VERSION ""

NS_ :

BS_:

BU_: DBW AKit Pacifica MPDM_Master MPDM_Requester

BO_ 3221225472 VECTOR__INDEPENDENT_SIG_MSG: 0 Vector__XXX
 SG_ DBW_PrndStateCmdMir : 4|3@1+ (1,0) [0|4] "Enum" Vector__XXX
 SG_ DBW_PrndParkBrakeStatus : 16|2@1+ (1,0) [0|3] "Enum" Vector__XXX
 SG_ AKit_PrndCtrlMode : 49|1@1+ (1,0) [0|1] "Bool" Vector__XXX
 SG_ AKit_PrndCtrlEnblCmd : 48|1@1+ (1,0) [0|1] "Bool" Vector__XXX
 SG_ AKit_MiscVehicleEnable : 0|1@1+ (1,0) [0|0] "" Vector__XXX

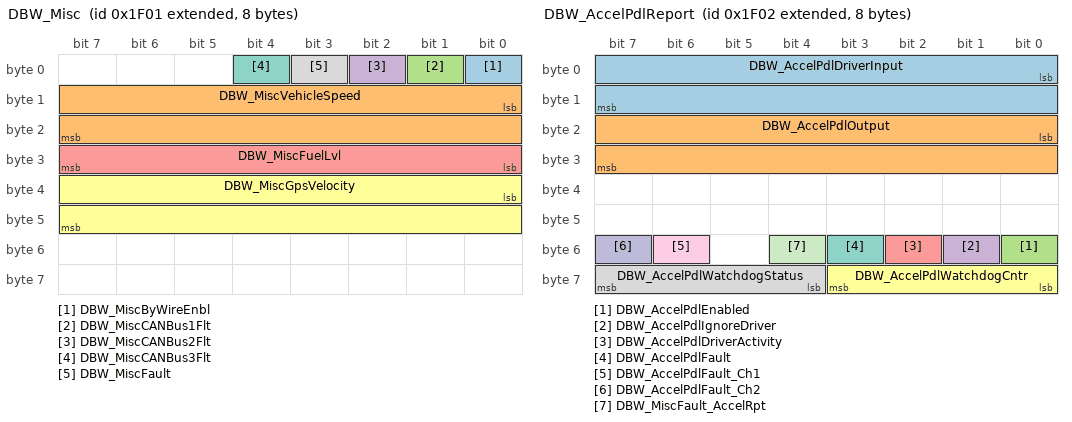
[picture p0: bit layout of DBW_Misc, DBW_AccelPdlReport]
BO_ 2147491585 DBW_Misc: 8 DBW
 SG_ DBW_MiscByWireEnbl : 0|1@1+ (1,0) [0|1] "Bool" Vector__XXX
 SG_ DBW_MiscVehicleSpeed : 8|16@1+ (0.0078125,0) [0|511.984] "km/h" Vector__XXX
 SG_ DBW_MiscCANBus1Flt : 1|1@1+ (1,0) [0|1] "Bool" Vector__XXX
 SG_ DBW_MiscCANBus2Flt : 2|1@1+ (1,0) [0|1] "Bool" Vector__XXX
 SG_ DBW_MiscFuelLvl : 24|8@1+ (0.5,0) [0|100] "%" Vector__XXX
 SG_ DBW_MiscGpsVelocity : 32|16@1+ (1,0) [0|0] "" Vector__XXX
 SG_ DBW_MiscCANBus3Flt : 4|1@1+ (1,0) [0|1] "Bool" Vector__XXX
 SG_ DBW_MiscFault : 3|1@1+ (1,0) [0|1] "Bool" Vector__XXX

BO_ 2147491586 DBW_AccelPdlReport: 8 DBW
 SG_ DBW_AccelPdlDriverInput : 0|16@1+ (1,0) [0|100] "%" Vector__XXX
 SG_ DBW_AccelPdlOutput : 16|16@1+ (1,0) [0|100] "%" Vector__XXX
 SG_ DBW_AccelPdlEnabled : 48|1@1+ (1,0) [0|1] "Bool" Vector__XXX
 SG_ DBW_AccelPdlIgnoreDriver : 49|1@1+ (1,0) [0|1] "Bool" Vector__XXX
 SG_ DBW_AccelPdlDriverActivity : 50|1@1+ (1,0) [0|1] "Bool" Vector__XXX
 SG_ DBW_AccelPdlWatchdogCntr : 56|4@1+ (1,0) [0|15] "" Vector__XXX
 SG_ DBW_AccelPdlFault : 51|1@1+ (1,0) [0|1] "Bool" Vector__XXX
 SG_ DBW_AccelPdlWatchdogStatus : 60|4@1+ (1,0) [0|15] "enum" Vector__XXX
 SG_ DBW_AccelPdlFault_Ch1 : 54|1@1+ (1,0) [0|1] "Bool" Vector__XXX
 SG_ DBW_AccelPdlFault_Ch2 : 55|1@1+ (1,0) [0|1] "Bool" Vector__XXX
 SG_ DBW_MiscFault_AccelRpt : 52|1@1+ (1,0) [0|1] "Bool" Vector__XXX

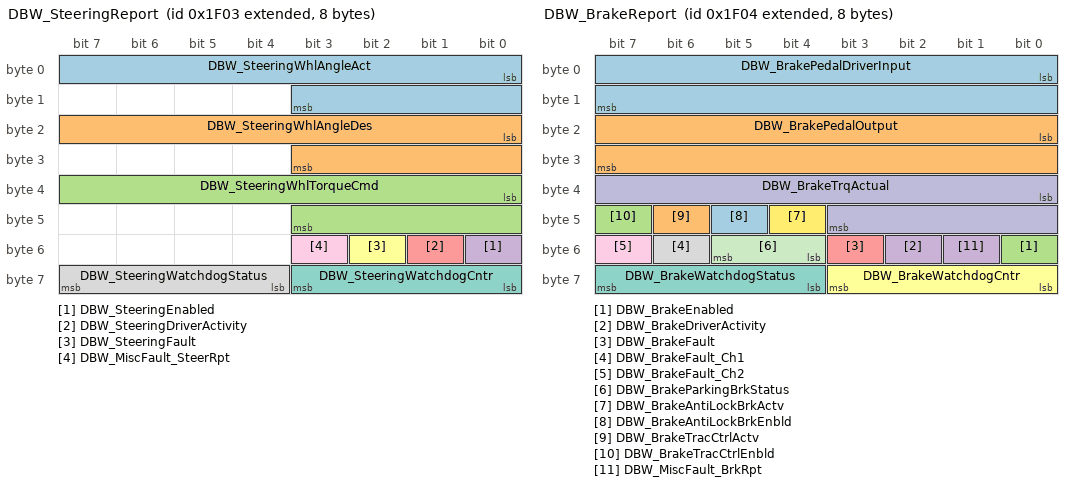
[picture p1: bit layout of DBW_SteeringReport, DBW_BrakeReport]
BO_ 2147491587 DBW_SteeringReport: 8 DBW
 SG_ DBW_SteeringWhlAngleAct : 0|12@1- (0.5,0) [-600|600] "deg" Vector__XXX
 SG_ DBW_SteeringWhlAngleDes : 16|12@1- (0.5,0) [-600|600] "deg" Vector__XXX
 SG_ DBW_SteeringWhlTorqueCmd : 32|12@1- (0.0078125,0) [-8|7.99219] "Nm" Vector__XXX
 SG_ DBW_SteeringEnabled : 48|1@1+ (1,0) [0|1] "Bool" Vector__XXX
 SG_ DBW_SteeringDriverActivity : 49|1@1+ (1,0) [0|1] "Bool" Vector__XXX
 SG_ DBW_SteeringFault : 50|1@1+ (1,0) [0|1] "Bool" Vector__XXX
 SG_ DBW_SteeringWatchdogCntr : 56|4@1+ (1,0) [0|15] "" Vector__XXX
 SG_ DBW_SteeringWatchdogStatus : 60|4@1+ (1,0) [0|15] "enum" Vector__XXX
 SG_ DBW_MiscFault_SteerRpt : 51|1@1+ (1,0) [0|1] "Bool" Vector__XXX

BO_ 2147491588 DBW_BrakeReport: 8 DBW
 SG_ DBW_BrakePedalDriverInput : 0|16@1+ (1,0) [0|100] "%" Vector__XXX
 SG_ DBW_BrakePedalOutput : 16|16@1+ (1,0) [0|100] "%" Vector__XXX
 SG_ DBW_BrakeEnabled : 48|1@1+ (1,0) [0|1] "Bool" Vector__XXX
 SG_ DBW_BrakeDriverActivity : 50|1@1+ (1,0) [0|1] "Bool" Vector__XXX
 SG_ DBW_BrakeFault : 51|1@1+ (1,0) [0|1] "Bool" Vector__XXX
 SG_ DBW_BrakeWatchdogCntr : 56|4@1+ (1,0) [0|15] "" Vector__XXX
 SG_ DBW_BrakeWatchdogStatus : 60|4@1+ (1,0) [0|15] "enum" Vector__XXX
 SG_ DBW_BrakeFault_Ch1 : 54|1@1+ (1,0) [0|1] "Bool" Vector__XXX
 SG_ DBW_BrakeFault_Ch2 : 55|1@1+ (1,0) [0|1] "Bool" Vector__XXX
 SG_ DBW_BrakeTrqActual : 32|12@1+ (3,0) [0|12282] "Nm" Vector__XXX
 SG_ DBW_BrakeParkingBrkStatus : 52|2@1+ (1,0) [0|3] "Enum" Vector__XXX
 SG_ DBW_BrakeAntiLockBrkActv : 44|1@1+ (1,0) [0|1] "Bool" Vector__XXX
 SG_ DBW_BrakeAntiLockBrkEnbld : 45|1@1+ (1,0) [0|1] "Bool" Vector__XXX
 SG_ DBW_BrakeTracCtrlActv : 46|1@1+ (1,0) [0|1] "Bool" Vector__XXX
 SG_ DBW_BrakeTracCtrlEnbld : 47|1@1+ (1,0) [0|1] "Bool" Vector__XXX
 SG_ DBW_MiscFault_BrkRpt : 49|1@1+ (1,0) [0|1] "Bool" Vector__XXX

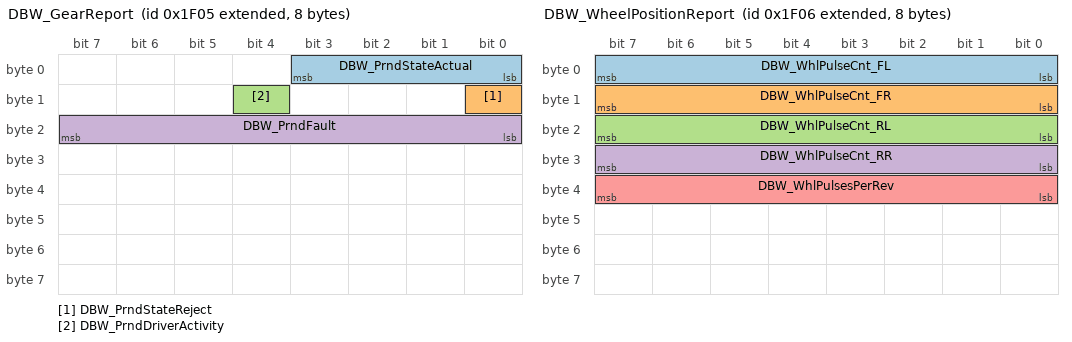
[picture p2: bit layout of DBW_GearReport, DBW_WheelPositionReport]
BO_ 2147491589 DBW_GearReport: 8 DBW
 SG_ DBW_PrndStateActual : 0|4@1+ (1,0) [0|4] "Enum" Vector__XXX
 SG_ DBW_PrndStateReject : 8|1@1+ (1,0) [0|1] "Bool" Vector__XXX
 SG_ DBW_PrndDriverActivity : 12|1@1+ (1,0) [0|1] "Bool" Vector__XXX
 SG_ DBW_PrndFault : 16|8@1+ (1,0) [0|1] "Bool" Vector__XXX

BO_ 2147491590 DBW_WheelPositionReport: 8 DBW
 SG_ DBW_WhlPulseCnt_FL : 0|8@1+ (1,0) [0|254] "Count" Vector__XXX
 SG_ DBW_WhlPulseCnt_FR : 8|8@1+ (1,0) [0|254] "Count" Vector__XXX
 SG_ DBW_WhlPulseCnt_RL : 16|8@1+ (1,0) [0|254] "Count" Vector__XXX
 SG_ DBW_WhlPulseCnt_RR : 24|8@1+ (1,0) [0|254] "Count" Vector__XXX
 SG_ DBW_WhlPulsesPerRev : 32|8@1+ (1,0) [0|255] "Count" Vector__XXX

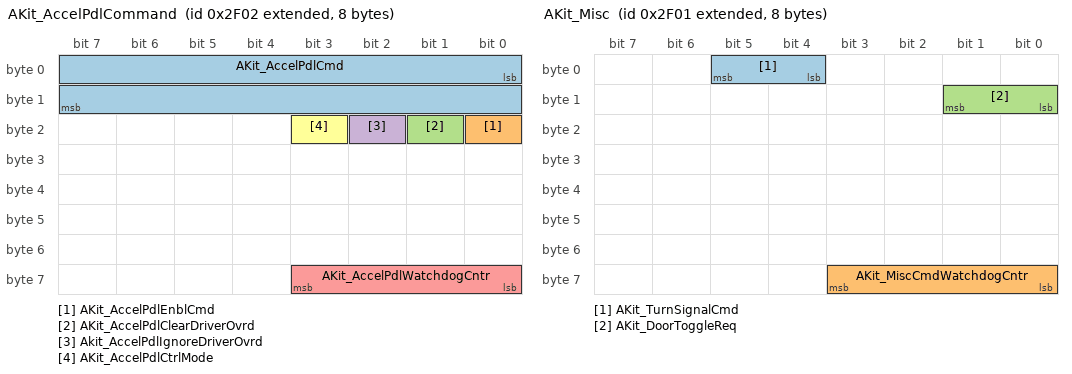
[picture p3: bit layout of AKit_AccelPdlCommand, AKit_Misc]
BO_ 2147495682 AKit_AccelPdlCommand: 8 AKit
 SG_ AKit_AccelPdlCmd : 0|16@1+ (1,0) [0|100] "%" Vector__XXX
 SG_ AKit_AccelPdlEnblCmd : 16|1@1+ (1,0) [0|1] "Bool" Vector__XXX
 SG_ AKit_AccelPdlClearDriverOvrd : 17|1@1+ (1,0) [0|1] "Bool" Vector__XXX
 SG_ Akit_AccelPdlIgnoreDriverOvrd : 18|1@1+ (1,0) [0|1] "Bool" Vector__XXX
 SG_ AKit_AccelPdlWatchdogCntr : 56|4@1+ (1,0) [0|15] "" Vector__XXX
 SG_ AKit_AccelPdlCtrlMode : 19|1@1+ (1,0) [0|1] "Enum" Vector__XXX

BO_ 2147495681 AKit_Misc: 8 AKit
 SG_ AKit_TurnSignalCmd : 4|2@1+ (1,0) [0|3] "Enum" Vector__XXX
 SG_ AKit_MiscCmdWatchdogCntr : 56|4@1+ (1,0) [0|15] "" Vector__XXX
 SG_ AKit_DoorToggleReq : 8|2@1+ (1,0) [0|3] "Enum" Vector__XXX

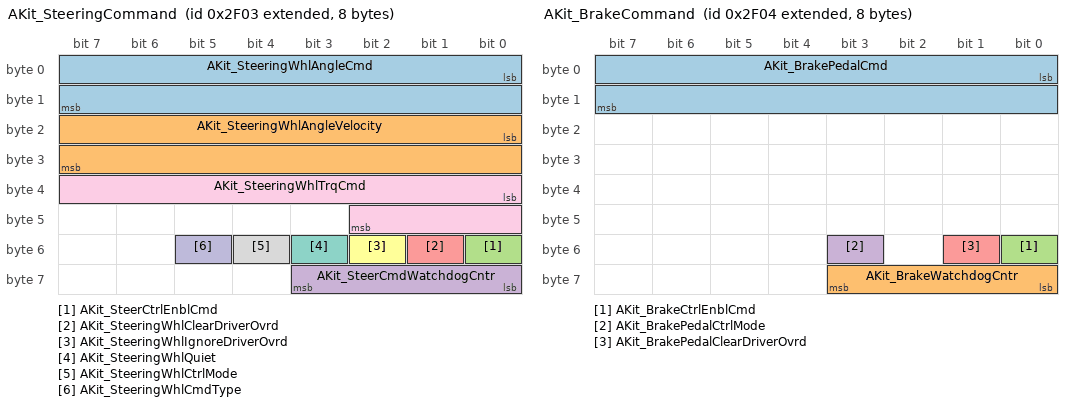
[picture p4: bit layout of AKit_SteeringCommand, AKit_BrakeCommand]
BO_ 2147495683 AKit_SteeringCommand: 8 AKit
 SG_ AKit_SteeringWhlAngleCmd : 0|16@1- (1,0) [-500|500] "deg" Vector__XXX
 SG_ AKit_SteeringWhlAngleVelocity : 16|16@1- (1,0) [0|498] "deg/s" Vector__XXX
 SG_ AKit_SteerCtrlEnblCmd : 48|1@1+ (1,0) [0|0] "" Vector__XXX
 SG_ AKit_SteerCmdWatchdogCntr : 56|4@1+ (1,0) [0|15] "" Vector__XXX
 SG_ AKit_SteeringWhlClearDriverOvrd : 49|1@1+ (1,0) [0|1] "" Vector__XXX
 SG_ AKit_SteeringWhlIgnoreDriverOvrd : 50|1@1+ (1,0) [0|1] "" Vector__XXX
 SG_ AKit_SteeringWhlQuiet : 51|1@1+ (1,0) [0|1] "" Vector__XXX
 SG_ AKit_SteeringWhlCtrlMode : 52|1@1+ (1,0) [0|0] "" Vector__XXX
 SG_ AKit_SteeringWhlTrqCmd : 32|11@1+ (0.0078125,-8) [-8|7.99219] "Nm" Vector__XXX
 SG_ AKit_SteeringWhlCmdType : 53|1@1+ (1,0) [0|1] "" Vector__XXX

BO_ 2147495684 AKit_BrakeCommand: 8 AKit
 SG_ AKit_BrakePedalCmd : 0|16@1+ (1,0) [0|100] "%" Vector__XXX
 SG_ AKit_BrakeWatchdogCntr : 56|4@1+ (1,0) [0|15] "" Vector__XXX
 SG_ AKit_BrakeCtrlEnblCmd : 48|1@1+ (1,0) [0|1] "Bool" Vector__XXX
 SG_ AKit_BrakePedalCtrlMode : 51|1@1+ (1,0) [0|1] "Enum" Vector__XXX
 SG_ AKit_BrakePedalClearDriverOvrd : 49|1@1+ (1,0) [0|1] "Bool" Vector__XXX

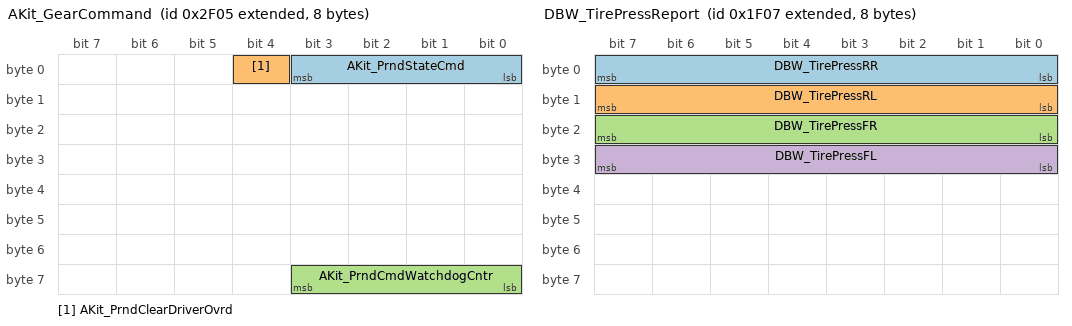
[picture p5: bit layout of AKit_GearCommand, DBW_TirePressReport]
BO_ 2147495685 AKit_GearCommand: 8 AKit
 SG_ AKit_PrndStateCmd : 0|4@1+ (1,0) [0|0] "Enum" Vector__XXX
 SG_ AKit_PrndClearDriverOvrd : 4|1@1+ (1,0) [0|0] "Bool" Vector__XXX
 SG_ AKit_PrndCmdWatchdogCntr : 56|4@1+ (1,0) [0|15] "" Vector__XXX

BO_ 2147491599 DBW_DriverInputs: 8 AKit
 SG_ DBW_OccupAnyDoorOrHoodAjar : 0|1@1+ (1,0) [0|1] "Bool" Vector__XXX
 SG_ DBW_OccupAnyAirbagDeployed : 8|1@1+ (1,0) [0|1] "Bool" Vector__XXX
 SG_ DBW_OccupAnySeatbeltUnbuckled : 16|1@1+ (1,0) [0|1] "Bool" Vector__XXX
 SG_ DBW_DrvInptCruiseResumeBtn : 24|1@1+ (1,0) [0|1] "Bool" Vector__XXX
 SG_ DBW_DrvInptCruiseCancelBtn : 25|1@1+ (1,0) [0|1] "Bool" Vector__XXX
 SG_ DBW_DrvInptCruiseAccelBtn : 26|1@1+ (1,0) [0|1] "Bool" Vector__XXX
 SG_ DBW_DrvInptCruiseDecelBtn : 27|1@1+ (1,0) [0|1] "Bool" Vector__XXX
 SG_ DBW_DrvInptCruiseOnOffBtn : 28|1@1+ (1,0) [0|1] "Bool" Vector__XXX
 SG_ DBW_DrvInptAccOnOffBtn : 29|1@1+ (1,0) [0|1] "Bool" Vector__XXX
 SG_ DBW_DrvInptAccIncDistBtn : 30|1@1+ (1,0) [0|1] "Bool" Vector__XXX
 SG_ DBW_DrvInptAccDecDistBtn : 31|1@1+ (1,0) [0|1] "Bool" Vector__XXX
 SG_ DBW_DrvInptHiBeam : 32|2@1+ (1,0) [0|3] "enum" Vector__XXX
 SG_ DBW_DrvInptTurnSignal : 34|2@1+ (1,0) [0|3] "enum" Vector__XXX
 SG_ DBW_DrvInptWiper : 36|4@1+ (1,0) [0|15] "enum" Vector__XXX
 SG_ DBW_OccupDrvDoorAjar : 1|1@1+ (1,0) [0|1] "Bool" Vector__XXX
 SG_ DBW_OccupPsgDoorAjar : 2|1@1+ (1,0) [0|1] "Bool" Vector__XXX
 SG_ DBW_OccupRlDoorAjar : 3|1@1+ (1,0) [0|1] "Bool" Vector__XXX
 SG_ DBW_OccupRrDoorAjar : 4|1@1+ (1,0) [0|1] "Bool" Vector__XXX
 SG_ DBW_OccupLiftgateAjar : 5|1@1+ (1,0) [0|1] "Bool" Vector__XXX

BO_ 2147491591 DBW_TirePressReport: 8 DBW
 SG_ DBW_TirePressRR : 0|8@1+ (6.89476,0) [0|868.739] "kPa" Vector__XXX
 SG_ DBW_TirePressRL : 8|8@1+ (6.89476,0) [0|868.739] "kPa" Vector__XXX
 SG_ DBW_TirePressFR : 16|8@1+ (6.89476,0) [0|868.739] "kPa" Vector__XXX
 SG_ DBW_TirePressFL : 24|8@1+ (6.89476,0) [0|868.739] "kPa" Vector__XXX

BO_ 2147491592 DBW_VinReport: 8 DBW
 SG_ DBW_VinMultiplexor M : 0|2@1+ (1,0) [0|2] "" Vector__XXX
 SG_ DBW_VinDigit_01 m0 : 8|8@1+ (1,0) [30|90] "ascii" Vector__XXX
 SG_ DBW_VinDigit_02 m0 : 16|8@1+ (1,0) [30|90] "ascii" Vector__XXX
 SG_ DBW_VinDigit_03 m0 : 24|8@1+ (1,0) [30|90] "ascii" Vector__XXX
 SG_ DBW_VinDigit_04 m0 : 32|8@1+ (1,0) [30|90] "ascii" Vector__XXX
 SG_ DBW_VinDigit_05 m0 : 40|8@1+ (1,0) [30|90] "ascii" Vector__XXX
 SG_ DBW_VinDigit_06 m0 : 48|8@1+ (1,0) [30|90] "ascii" Vector__XXX
 SG_ DBW_VinDigit_07 m0 : 56|8@1+ (1,0) [30|90] "ascii" Vector__XXX
 SG_ DBW_VinDigit_08 m1 : 8|8@1+ (1,0) [30|90] "ascii" Vector__XXX
 SG_ DBW_VinDigit_09 m1 : 16|8@1+ (1,0) [30|90] "ascii" Vector__XXX
 SG_ DBW_VinDigit_10 m1 : 24|8@1+ (1,0) [30|90] "ascii" Vector__XXX
 SG_ DBW_VinDigit_11 m1 : 32|8@1+ (1,0) [30|90] "ascii" Vector__XXX
 SG_ DBW_VinDigit_12 m1 : 40|8@1+ (1,0) [30|90] "ascii" Vector__XXX
 SG_ DBW_VinDigit_13 m1 : 48|8@1+ (1,0) [30|90] "ascii" Vector__XXX
 SG_ DBW_VinDigit_14 m1 : 56|8@1+ (1,0) [30|90] "ascii" Vector__XXX
 SG_ DBW_VinDigit_15 m2 : 8|8@1+ (1,0) [30|90] "ascii" Vector__XXX
 SG_ DBW_VinDigit_16 m2 : 16|8@1+ (1,0) [30|90] "ascii" Vector__XXX
 SG_ DBW_VinDigit_17 m2 : 24|8@1+ (1,0) [30|90] "ascii" Vector__XXX

BO_ 2147491593 DBW_GpsReport: 8 DBW
 SG_ DBW_GpsLong : 0|32@1+ (0.301749,0) [-648000000|648000000] "mas" Vector__XXX
 SG_ DBW_GpsLat : 32|32@1+ (0.301749,0) [-324000000|324000000] "mas" Vector__XXX

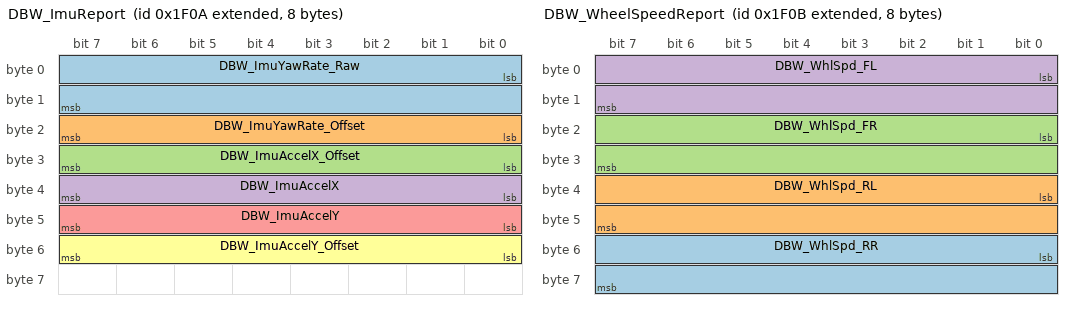
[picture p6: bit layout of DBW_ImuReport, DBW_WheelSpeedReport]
BO_ 2147491594 DBW_ImuReport: 8 DBW
 SG_ DBW_ImuYawRate_Raw : 0|16@1+ (0.01,-327.68) [-327.68|327.66] "deg/sec" Vector__XXX
 SG_ DBW_ImuYawRate_Offset : 16|8@1+ (0.08,-10.24) [-6.96|6.96] "" Vector__XXX
 SG_ DBW_ImuAccelX_Offset : 24|8@1+ (0.02,-2.56) [-2.56|2.52] "m/s/s" Vector__XXX
 SG_ DBW_ImuAccelX : 32|8@1+ (0.08,-10.24) [-10.24|10.08] "m/s/s" Vector__XXX
 SG_ DBW_ImuAccelY : 40|8@1+ (0.08,-10.24) [-10.24|10.08] "m/s/s" Vector__XXX
 SG_ DBW_ImuAccelY_Offset : 48|8@1+ (0.02,-2.56) [-2.56|2.52] "m/s/s" Vector__XXX

BO_ 2147491595 DBW_WheelSpeedReport: 8 DBW
 SG_ DBW_WhlSpd_RR : 48|16@1+ (0.5,-8192) [-8192|8191] "rpm" Vector__XXX
 SG_ DBW_WhlSpd_RL : 32|16@1+ (0.5,-8192) [-8192|8191] "rpm" Vector__XXX
 SG_ DBW_WhlSpd_FR : 16|16@1+ (0.5,-8192) [-8192|8191] "rpm" Vector__XXX
 SG_ DBW_WhlSpd_FL : 0|16@1+ (0.5,-8192) [-8192|8191] "rpm" Vector__XXX

BO_ 2147491597 Mpdm1Report: 8 MPDM_Master
 SG_ DBW_Mdpm1Fuse01 : 0|2@1+ (1,0) [0|3] "enum" Vector__XXX
 SG_ DBW_Mdpm1Fuse02 : 2|2@1+ (1,0) [0|3] "enum" Vector__XXX
 SG_ DBW_Mdpm1Fuse03 : 4|2@1+ (1,0) [0|3] "enum" Vector__XXX
 SG_ DBW_Mdpm1Fuse04 : 6|2@1+ (1,0) [0|3] "enum" Vector__XXX
 SG_ DBW_Mdpm1Fuse05 : 8|2@1+ (1,0) [0|3] "enum" Vector__XXX
 SG_ DBW_Mdpm1Fuse06 : 10|2@1+ (1,0) [0|3] "enum" Vector__XXX
 SG_ DBW_Mdpm1Fuse07 : 12|2@1+ (1,0) [0|3] "enum" Vector__XXX
 SG_ DBW_Mdpm1Fuse08 : 14|2@1+ (1,0) [0|3] "enum" Vector__XXX
 SG_ DBW_Mdpm1Fuse09 : 16|2@1+ (1,0) [0|3] "enum" Vector__XXX
 SG_ DBW_Mdpm1Fuse10 : 18|2@1+ (1,0) [0|3] "enum" Vector__XXX
 SG_ DBW_Mdpm1Fuse11 : 20|2@1+ (1,0) [0|3] "enum" Vector__XXX
 SG_ DBW_Mdpm1Fuse12 : 22|2@1+ (1,0) [0|3] "enum" Vector__XXX
 SG_ DBW_Mdpm1Fuse13 : 24|2@1+ (1,0) [0|3] "enum" Vector__XXX
 SG_ DBW_Mdpm1Fuse14 : 26|2@1+ (1,0) [0|3] "enum" Vector__XXX
 SG_ DBW_Mdpm1Fuse15 : 28|2@1+ (1,0) [0|3] "enum" Vector__XXX
 SG_ DBW_Mdpm1Fuse16 : 30|2@1+ (1,0) [0|3] "enum" Vector__XXX
 SG_ DBW_Mdpm1Relay01 : 32|4@1+ (1,0) [0|15] "enum" Vector__XXX
 SG_ DBW_Mdpm1Relay02 : 36|4@1+ (1,0) [0|15] "enum" Vector__XXX
 SG_ DBW_Mdpm1Relay03 : 40|4@1+ (1,0) [0|15] "enum" Vector__XXX
 SG_ DBW_Mdpm1Relay04 : 44|4@1+ (1,0) [0|15] "enum" Vector__XXX
 SG_ DBW_Mdpm1Relay05 : 48|4@1+ (1,0) [0|15] "enum" Vector__XXX
 SG_ DBW_Mdpm1Relay06 : 52|4@1+ (1,0) [0|15] "enum" Vector__XXX
 SG_ DBW_Mdpm1Relay07 : 56|4@1+ (1,0) [0|15] "enum" Vector__XXX
 SG_ DBW_Mdpm1Relay08 : 60|4@1+ (1,0) [0|15] "enum" Vector__XXX

BO_ 2147491598 Mpdm2Report: 8 MPDM_Master
 SG_ DBW_Mdpm2Fuse01 : 0|2@1+ (1,0) [0|3] "enum" Vector__XXX
 SG_ DBW_Mdpm2Fuse02 : 2|2@1+ (1,0) [0|3] "enum" Vector__XXX
 SG_ DBW_Mdpm2Fuse03 : 4|2@1+ (1,0) [0|3] "enum" Vector__XXX
 SG_ DBW_Mdpm2Fuse04 : 6|2@1+ (1,0) [0|3] "enum" Vector__XXX
 SG_ DBW_Mdpm2Fuse05 : 8|2@1+ (1,0) [0|3] "enum" Vector__XXX
 SG_ DBW_Mdpm2Fuse06 : 10|2@1+ (1,0) [0|3] "enum" Vector__XXX
 SG_ DBW_Mdpm2Fuse07 : 12|2@1+ (1,0) [0|3] "enum" Vector__XXX
 SG_ DBW_Mdpm2Fuse08 : 14|2@1+ (1,0) [0|3] "enum" Vector__XXX
 SG_ DBW_Mdpm2Fuse09 : 16|2@1+ (1,0) [0|3] "enum" Vector__XXX
 SG_ DBW_Mdpm2Fuse10 : 18|2@1+ (1,0) [0|3] "enum" Vector__XXX
 SG_ DBW_Mdpm2Fuse11 : 20|2@1+ (1,0) [0|3] "enum" Vector__XXX
 SG_ DBW_Mdpm2Fuse12 : 22|2@1+ (1,0) [0|3] "enum" Vector__XXX
 SG_ DBW_Mdpm2Fuse13 : 24|2@1+ (1,0) [0|3] "enum" Vector__XXX
 SG_ DBW_Mdpm2Fuse14 : 26|2@1+ (1,0) [0|3] "enum" Vector__XXX
 SG_ DBW_Mdpm2Fuse15 : 28|2@1+ (1,0) [0|3] "enum" Vector__XXX
 SG_ DBW_Mdpm2Fuse16 : 30|2@1+ (1,0) [0|3] "enum" Vector__XXX
 SG_ DBW_Mdpm2Relay01 : 32|4@1+ (1,0) [0|15] "enum" Vector__XXX
 SG_ DBW_Mdpm2Relay02 : 36|4@1+ (1,0) [0|15] "enum" Vector__XXX
 SG_ DBW_Mdpm2Relay03 : 40|4@1+ (1,0) [0|15] "enum" Vector__XXX
 SG_ DBW_Mdpm2Relay04 : 44|4@1+ (1,0) [0|15] "enum" Vector__XXX
 SG_ DBW_Mdpm2Relay05 : 48|4@1+ (1,0) [0|15] "enum" Vector__XXX
 SG_ DBW_Mdpm2Relay06 : 52|4@1+ (1,0) [0|15] "enum" Vector__XXX
 SG_ DBW_Mdpm2Relay07 : 56|4@1+ (1,0) [0|15] "enum" Vector__XXX
 SG_ DBW_Mdpm2Relay08 : 60|4@1+ (1,0) [0|15] "enum" Vector__XXX

BO_ 2147495686 MdpmCommand: 8 MPDM_Requester
 SG_ AKit_Mdpm1Relay01Cmd : 0|2@1+ (1,0) [0|3] "enum" Vector__XXX
 SG_ AKit_Mdpm1Relay02Cmd : 2|2@1+ (1,0) [0|3] "enum" Vector__XXX
 SG_ AKit_Mdpm1Relay03Cmd : 4|2@1+ (1,0) [0|3] "enum" Vector__XXX
 SG_ AKit_Mdpm1Relay04Cmd : 6|2@1+ (1,0) [0|3] "enum" Vector__XXX
 SG_ AKit_Mdpm1Relay05Cmd : 8|2@1+ (1,0) [0|3] "enum" Vector__XXX
 SG_ AKit_Mdpm1Relay06Cmd : 10|2@1+ (1,0) [0|3] "enum" Vector__XXX
 SG_ AKit_Mdpm1Relay07Cmd : 12|2@1+ (1,0) [0|3] "enum" Vector__XXX
 SG_ AKit_Mdpm1Relay08Cmd : 14|2@1+ (1,0) [0|3] "enum" Vector__XXX
 SG_ AKit_Mdpm2Relay01Cmd : 16|2@1+ (1,0) [0|3] "enum" Vector__XXX
 SG_ AKit_Mdpm2Relay02Cmd : 18|2@1+ (1,0) [0|3] "enum" Vector__XXX
 SG_ AKit_Mdpm2Relay03Cmd : 20|2@1+ (1,0) [0|3] "enum" Vector__XXX
 SG_ AKit_Mdpm2Relay04Cmd : 22|2@1+ (1,0) [0|3] "enum" Vector__XXX
 SG_ AKit_Mdpm2Relay05Cmd : 24|2@1+ (1,0) [0|3] "enum" Vector__XXX
 SG_ AKit_Mdpm2Relay06Cmd : 26|2@1+ (1,0) [0|3] "enum" Vector__XXX
 SG_ AKit_Mdpm2Relay07Cmd : 28|2@1+ (1,0) [0|3] "enum" Vector__XXX
 SG_ AKit_Mdpm2Relay08Cmd : 30|2@1+ (1,0) [0|3] "enum" Vector__XXX
 SG_ AKit_MdpmCmdWatchdogCntr : 56|4@1+ (1,0) [0|3] "" Vector__XXX

BO_ 992 PacificaVINmsg: 8 Pacifica
 SG_ VinMultiplexor M : 0|2@1+ (1,0) [0|2] "" Vector__XXX
 SG_ VinDigit_01 m0 : 8|8@1+ (1,0) [30|90] "ascii" Vector__XXX
 SG_ VinDigit_02 m0 : 16|8@1+ (1,0) [30|90] "ascii" Vector__XXX
 SG_ VinDigit_03 m0 : 24|8@1+ (1,0) [30|90] "ascii" Vector__XXX
 SG_ VinDigit_04 m0 : 32|8@1+ (1,0) [30|90] "ascii" Vector__XXX
 SG_ VinDigit_05 m0 : 40|8@1+ (1,0) [30|90] "ascii" Vector__XXX
 SG_ VinDigit_06 m0 : 48|8@1+ (1,0) [30|90] "ascii" Vector__XXX
 SG_ VinDigit_07 m0 : 56|8@1+ (1,0) [30|90] "ascii" Vector__XXX
 SG_ VinDigit_08 m1 : 8|8@1+ (1,0) [30|90] "ascii" Vector__XXX
 SG_ VinDigit_09 m1 : 16|8@1+ (1,0) [30|90] "ascii" Vector__XXX
 SG_ VinDigit_10 m1 : 24|8@1+ (1,0) [30|90] "ascii" Vector__XXX
 SG_ VinDigit_11 m1 : 32|8@1+ (1,0) [30|90] "ascii" Vector__XXX
 SG_ VinDigit_12 m1 : 40|8@1+ (1,0) [30|90] "ascii" Vector__XXX
 SG_ VinDigit_13 m1 : 48|8@1+ (1,0) [30|90] "ascii" Vector__XXX
 SG_ VinDigit_14 m1 : 56|8@1+ (1,0) [30|90] "ascii" Vector__XXX
 SG_ VinDigit_15 m2 : 8|8@1+ (1,0) [30|90] "ascii" Vector__XXX
 SG_ VinDigit_16 m2 : 16|8@1+ (1,0) [30|90] "ascii" Vector__XXX
 SG_ VinDigit_17 m2 : 24|8@1+ (1,0) [30|90] "ascii" Vector__XXX

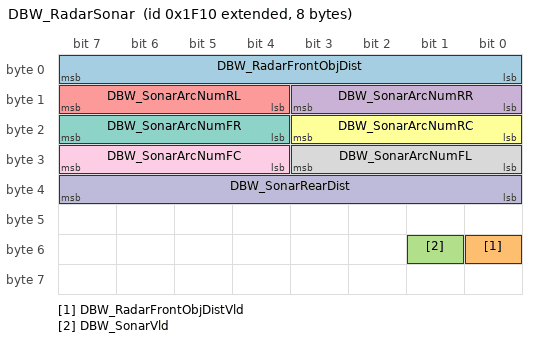
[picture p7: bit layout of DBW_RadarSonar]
BO_ 2147491600 DBW_RadarSonar: 8 DBW
 SG_ DBW_RadarFrontObjDist : 0|8@1+ (1,0) [0|253] "m" Vector__XXX
 SG_ DBW_RadarFrontObjDistVld : 48|1@1+ (1,0) [0|1] "Bool" Vector__XXX
 SG_ DBW_SonarVld : 49|1@1+ (1,0) [0|1] "Bool" Vector__XXX
 SG_ DBW_SonarArcNumRR : 8|4@1+ (1,0) [0|0] "Enum" Vector__XXX
 SG_ DBW_SonarArcNumRL : 12|4@1+ (1,0) [0|0] "Enum" Vector__XXX
 SG_ DBW_SonarArcNumRC : 16|4@1+ (1,0) [0|0] "Enum" Vector__XXX
 SG_ DBW_SonarArcNumFR : 20|4@1+ (1,0) [0|0] "Enum" Vector__XXX
 SG_ DBW_SonarArcNumFL : 24|4@1+ (1,0) [0|0] "Enum" Vector__XXX
 SG_ DBW_SonarArcNumFC : 28|4@1+ (1,0) [0|0] "Enum" Vector__XXX
 SG_ DBW_SonarRearDist : 32|8@1+ (0.01,0) [0|2.54] "m" Vector__XXX

BO_ 1807 DBW_FaultText: 8 DBW
 SG_ FltTxt_PageNum M : 0|8@1+ (1,0) [0|255] "" Vector__XXX
 SG_ FltTxt_FaultId m0 : 15|16@0+ (1,0) [0|65535] "" Vector__XXX
 SG_ FltTxt_NumPages m0 : 40|8@1+ (1,0) [0|10] "" Vector__XXX
 SG_ FltTxt_FaultStatus m0 : 48|8@1+ (1,0) [0|2] "enum" Vector__XXX
 SG_ FltTxt_FaultSetRuntime m255 : 15|32@0+ (1,0) [0|0] "ms" Vector__XXX
 SG_ FltTxt_CRC m255 : 56|8@1+ (1,0) [0|255] "" Vector__XXX
 SG_ FltTxt_CurrentRuntime m254 : 39|32@0+ (1,0) [0|0] "ms" Vector__XXX
 SG_ FltTxt_Char01 m1 : 8|8@1+ (1,0) [0|255] "ascii" Vector__XXX
 SG_ FltTxt_Char02 m1 : 16|8@1+ (1,0) [0|255] "ascii" Vector__XXX
 SG_ FltTxt_Char03 m1 : 24|8@1+ (1,0) [0|255] "ascii" Vector__XXX
 SG_ FltTxt_Char04 m1 : 32|8@1+ (1,0) [0|255] "ascii" Vector__XXX
 SG_ FltTxt_Char05 m1 : 40|8@1+ (1,0) [0|255] "ascii" Vector__XXX
 SG_ FltTxt_Char06 m1 : 48|8@1+ (1,0) [0|255] "ascii" Vector__XXX
 SG_ FltTxt_Char07 m1 : 56|8@1+ (1,0) [0|255] "ascii" Vector__XXX
 SG_ FltTxt_Char08 m2 : 8|8@1+ (1,0) [0|255] "ascii" Vector__XXX
 SG_ FltTxt_Char09 m2 : 16|8@1+ (1,0) [0|255] "ascii" Vector__XXX
 SG_ FltTxt_Char10 m2 : 24|8@1+ (1,0) [0|255] "ascii" Vector__XXX
 SG_ FltTxt_Char11 m2 : 32|8@1+ (1,0) [0|255] "ascii" Vector__XXX
 SG_ FltTxt_Char12 m2 : 40|8@1+ (1,0) [0|255] "ascii" Vector__XXX
 SG_ FltTxt_Char13 m2 : 48|8@1+ (1,0) [0|255] "ascii" Vector__XXX
 SG_ FltTxt_Char14 m2 : 56|8@1+ (1,0) [0|255] "ascii" Vector__XXX
 SG_ FltTxt_Char15 m3 : 8|8@1+ (1,0) [0|255] "ascii" Vector__XXX
 SG_ FltTxt_Char16 m3 : 16|8@1+ (1,0) [0|255] "ascii" Vector__XXX
 SG_ FltTxt_Char17 m3 : 24|8@1+ (1,0) [0|255] "ascii" Vector__XXX
 SG_ FltTxt_Char18 m3 : 32|8@1+ (1,0) [0|255] "ascii" Vector__XXX
 SG_ FltTxt_Char19 m3 : 40|8@1+ (1,0) [0|255] "ascii" Vector__XXX
 SG_ FltTxt_Char20 m3 : 48|8@1+ (1,0) [0|255] "ascii" Vector__XXX
 SG_ FltTxt_Char21 m3 : 56|8@1+ (1,0) [0|255] "ascii" Vector__XXX
 SG_ FltTxt_Char22 m4 : 8|8@1+ (1,0) [0|255] "ascii" Vector__XXX
 SG_ FltTxt_Char23 m4 : 16|8@1+ (1,0) [0|255] "ascii" Vector__XXX
 SG_ FltTxt_Char24 m4 : 24|8@1+ (1,0) [0|255] "ascii" Vector__XXX
 SG_ FltTxt_Char25 m4 : 32|8@1+ (1,0) [0|255] "ascii" Vector__XXX
 SG_ FltTxt_Char26 m4 : 40|8@1+ (1,0) [0|255] "ascii" Vector__XXX
 SG_ FltTxt_Char27 m4 : 48|8@1+ (1,0) [0|255] "ascii" Vector__XXX
 SG_ FltTxt_Char28 m4 : 56|8@1+ (1,0) [0|255] "ascii" Vector__XXX
 SG_ FltTxt_Char29 m5 : 8|8@1+ (1,0) [0|255] "ascii" Vector__XXX
 SG_ FltTxt_Char30 m5 : 16|8@1+ (1,0) [0|255] "ascii" Vector__XXX
 SG_ FltTxt_Char31 m5 : 24|8@1+ (1,0) [0|255] "ascii" Vector__XXX
 SG_ FltTxt_Char32 m5 : 32|8@1+ (1,0) [0|255] "ascii" Vector__XXX
 SG_ FltTxt_Char33 m5 : 40|8@1+ (1,0) [0|255] "ascii" Vector__XXX
 SG_ FltTxt_Char34 m5 : 48|8@1+ (1,0) [0|255] "ascii" Vector__XXX
 SG_ FltTxt_Char35 m5 : 56|8@1+ (1,0) [0|255] "ascii" Vector__XXX
 SG_ FltTxt_Char36 m6 : 8|8@1+ (1,0) [0|255] "ascii" Vector__XXX
 SG_ FltTxt_Char37 m6 : 16|8@1+ (1,0) [0|255] "ascii" Vector__XXX
 SG_ FltTxt_Char38 m6 : 24|8@1+ (1,0) [0|255] "ascii" Vector__XXX
 SG_ FltTxt_Char39 m6 : 32|8@1+ (1,0) [0|255] "ascii" Vector__XXX
 SG_ FltTxt_Char40 m6 : 40|8@1+ (1,0) [0|255] "ascii" Vector__XXX
 SG_ FltTxt_Char41 m6 : 48|8@1+ (1,0) [0|255] "ascii" Vector__XXX
 SG_ FltTxt_Char42 m6 : 56|8@1+ (1,0) [0|255] "ascii" Vector__XXX
 SG_ FltTxt_Char43 m7 : 8|8@1+ (1,0) [0|255] "ascii" Vector__XXX
 SG_ FltTxt_Char44 m7 : 16|8@1+ (1,0) [0|255] "ascii" Vector__XXX
 SG_ FltTxt_Char45 m7 : 24|8@1+ (1,0) [0|255] "ascii" Vector__XXX
 SG_ FltTxt_Char46 m7 : 32|8@1+ (1,0) [0|255] "ascii" Vector__XXX
 SG_ FltTxt_Char47 m7 : 40|8@1+ (1,0) [0|255] "ascii" Vector__XXX
 SG_ FltTxt_Char48 m7 : 48|8@1+ (1,0) [0|255] "ascii" Vector__XXX
 SG_ FltTxt_Char49 m7 : 56|8@1+ (1,0) [0|255] "ascii" Vector__XXX

CM_ BU_ Pacifica "Just added a custom VIN-read message from this module";
CM_ BU_ MPDM_Master "Whichever module directly controls MPDM would be the MPDM Master (broadcasts status to other modules)";
CM_ BU_ MPDM_Requester "Any module that doesn't directly control the MPDM but might want to request a state would be an MPDM_Requester";
CM_ SG_ 3221225472 DBW_PrndParkBrakeStatus "move to brake message?";
CM_ SG_ 3221225472 AKit_PrndCtrlMode "If in joystick mode, the DBW controller may apply clips, rate limits, and vehicle speed adjustments to the commanded value for better stability (because joysticks are very hard to use to control a real vehicle). In Fully Autonomous mode, though, the DBW controller will not clip or rate limit the commanded actuator value.";
CM_ SG_ 3221225472 AKit_MiscVehicleEnable "what exactly are we enabling?";
CM_ SG_ 2147491585 DBW_MiscByWireEnbl "Actual mode of the Drive-By-Wire system.";
CM_ SG_ 2147491585 DBW_MiscVehicleSpeed "scaled to match Pacifica's vehicle speed message";
CM_ SG_ 2147491585 DBW_MiscCANBus1Flt "This just indicates that the other CAN bus is down?";
CM_ SG_ 2147491585 DBW_MiscCANBus2Flt "This just indicates that the other CAN bus is down?";
CM_ SG_ 2147491585 DBW_MiscFuelLvl "DBW will have to read IC_A1:AvgFuelLvl (liters) from the Pacifica and divide it by VehCfg3:VC_FUEL_CAP";
CM_ SG_ 2147491585 DBW_MiscFault "indicates one of the DBW actuators has faulted out. See individual report messages for more details.";
CM_ BO_ 2147491586 "was \"ThrottleReport\" message in spreadsheet, but that was confusing with the other \"ThrottleInfoReport\" message, so I changed this to AccelPdlReport for clarity";
CM_ SG_ 2147491586 DBW_AccelPdlIgnoreDriver "indicates the DBW system was commanded by the AKit to ignore the driver's input.";
CM_ SG_ 2147491586 DBW_AccelPdlDriverActivity "Driver is pressing the accel pedal, which will switch the DBW system to manual mode unless the AKit is sending the AccelPdlIgnoreDriver flag";
CM_ SG_ 2147491586 DBW_AccelPdlWatchdogCntr "Watchdog alive rolling counter";
CM_ SG_ 2147491586 DBW_AccelPdlFault "AccelPdl system has a fault, either from the vehicle itself or from an error in the command message from the AKit";
CM_ SG_ 2147491586 DBW_AccelPdlFault_Ch1 "VCU has detected hardware fault on accel pedal sig 1";
CM_ SG_ 2147491586 DBW_AccelPdlFault_Ch2 "VCU has detected hardware fault on accel pedal sig 2";
CM_ SG_ 2147491586 DBW_MiscFault_AccelRpt "Same signal as DBW_MiscFault in the DBW_Misc message. Just duplicated here so it's easier to read on-screen in the ROS data viewing utility.";
CM_ SG_ 2147491587 DBW_SteeringWhlAngleAct "Actual position of the steering wheel";
CM_ SG_ 2147491587 DBW_SteeringWhlAngleDes "Position that the DBW is trying to acheive.";
CM_ SG_ 2147491587 DBW_SteeringWhlTorqueCmd "Torque requested by the DBW to acheive the desired position";
CM_ SG_ 2147491587 DBW_SteeringDriverActivity "Driver is turning the steering wheel, which will switch the DBW system to Manual mode";
CM_ SG_ 2147491587 DBW_SteeringFault "Brake system has a fault, either from the vehicle itself or from an error in the command message from the AKit";
CM_ SG_ 2147491587 DBW_MiscFault_SteerRpt "Same signal as DBW_MiscFault in the DBW_Misc message. Just duplicated here so it's easier to read on-screen in the ROS data viewing utility.";
CM_ BO_ 2147491588 "same as \"BrakeInfoReport\" in other system";
CM_ SG_ 2147491588 DBW_BrakePedalDriverInput "Position of actual driver requested brake pedal";
CM_ SG_ 2147491588 DBW_BrakePedalOutput "Brake pedal command sent to vehicle";
CM_ SG_ 2147491588 DBW_BrakeEnabled "Brake control enabled";
CM_ SG_ 2147491588 DBW_BrakeDriverActivity "Driver is pressing the brakes, which will switch the DBW system to Manual mode";
CM_ SG_ 2147491588 DBW_BrakeFault "Brake system has a fault, either from the vehicle itself or from an error in the command message from the AKit";
CM_ SG_ 2147491588 DBW_BrakeWatchdogCntr "Watchdog alive rolling counter";
CM_ SG_ 2147491588 DBW_BrakeFault_Ch1 "VCU has detected hardware fault on brake sig 1";
CM_ SG_ 2147491588 DBW_BrakeFault_Ch2 "VCU has detected hardware fault on brake sig 2";
CM_ SG_ 2147491588 DBW_BrakeTrqActual "actual brake torque";
CM_ SG_ 2147491588 DBW_MiscFault_BrkRpt "Same signal as DBW_MiscFault in the DBW_Misc message. Just duplicated here so it's easier to read on-screen in the ROS data viewing utility.";
CM_ SG_ 2147491589 DBW_PrndStateReject "may make this an enum later, after more testing";
CM_ SG_ 2147491589 DBW_PrndDriverActivity "indicates the driver is turning the shift knob";
CM_ SG_ 2147491589 DBW_PrndFault "Gear select system has a fault, either from the vehicle itself or from an error in the command message from the AKit";
CM_ SG_ 2147491590 DBW_WhlPulseCnt_FL "Wheel pulse counter";
CM_ SG_ 2147491590 DBW_WhlPulseCnt_FR "Wheel pulse counter";
CM_ SG_ 2147491590 DBW_WhlPulseCnt_RL "Wheel pulse counter";
CM_ SG_ 2147491590 DBW_WhlPulseCnt_RR "Wheel pulse counter";
CM_ SG_ 2147491590 DBW_WhlPulsesPerRev "Number of wheel pulses in one revolution (96 for this vehicle)";
CM_ SG_ 2147495682 AKit_AccelPdlCmd "spec is in a unitless 0.15-0.5 scale, but Pacifica is in %. Which should the DBW use?";
CM_ SG_ 2147495682 AKit_AccelPdlEnblCmd "Is this enabling the pedal itself, or enabling overriding the pedal by the By-Wire system (aka disabling the actual pedal)?";
CM_ SG_ 2147495682 AKit_AccelPdlClearDriverOvrd "What does \"clear driver override\" mean?";
CM_ SG_ 2147495682 Akit_AccelPdlIgnoreDriverOvrd "When would we ever ignore a driver override?";
CM_ SG_ 2147495682 AKit_AccelPdlWatchdogCntr "Watchdog alive rolling counter";
CM_ SG_ 2147495682 AKit_AccelPdlCtrlMode "If in joystick mode, the DBW controller may apply clips, rate limits, and vehicle speed adjustments to the commanded value for better stability (because joysticks are very hard to use to control a real vehicle). In Fully Autonomous mode, though, the DBW controller will not clip or rate limit the commanded actuator value.";
CM_ BO_ 2147495681 "do we also need headlight commands?";
CM_ SG_ 2147495681 AKit_TurnSignalCmd "can't do hazards on pacifica currently";
CM_ SG_ 2147495681 AKit_MiscCmdWatchdogCntr "Watchdog alive rolling counter";
CM_ SG_ 2147495681 AKit_DoorToggleReq "Toggle the state of a given door. The event is edge-triggered in the DBW module when this signal transitions from one value to another, so if the request is sent for more than one message, the actual door will only move once.";
CM_ SG_ 2147495683 AKit_SteeringWhlAngleVelocity "0 = infinite rate limit.";
CM_ SG_ 2147495683 AKit_SteerCmdWatchdogCntr "Watchdog alive rolling counter";
CM_ SG_ 2147495683 AKit_SteeringWhlIgnoreDriverOvrd "I'm not sure that we can ignore driver overrides. If the driver grabs the wheel, the EPS module internally detects the driver \"hands-on-wheel\" and disables external steering torque requests";
CM_ SG_ 2147495683 AKit_SteeringWhlQuiet "What does \"quiet\" mean???";
CM_ SG_ 2147495683 AKit_SteeringWhlCtrlMode "If in joystick mode, the DBW controller may apply clips, rate limits, and vehicle speed adjustments to the commanded value for better stability (because joysticks are very hard to use to control a real vehicle). In Fully Autonomous mode, though, the DBW controller will not clip or rate limit the commanded actuator value. 0 must be joystick mode, that way if this signal is not implemented in the TX'ing module, the system will default to the more restrictive value.";
CM_ SG_ 2147495683 AKit_SteeringWhlTrqCmd "commanded steering wheel torque. Used in lieu of AKit_SteeringWhlAnglCmd if the AKit is going to handle the PID control to acheive a desired position. It's size and scaling was selected to match the command used over the vehicle's powertrain bus";
CM_ SG_ 2147495683 AKit_SteeringWhlCmdType "indicates whether the DBW system should follow the angle or torque command. 0 = angle command (PID done in DBW). 1 = torque command (ROS computer handles PID control.";
CM_ SG_ 2147495684 AKit_BrakeWatchdogCntr "Watchdog alive rolling counter";
CM_ SG_ 2147495684 AKit_BrakePedalCtrlMode "If in joystick mode, the DBW controller may apply clips, rate limits, and vehicle speed adjustments to the commanded value for better stability (because joysticks are very hard to use to control a real vehicle). In Fully Autonomous mode, though, the DBW controller will not clip or rate limit the commanded actuator value.";
CM_ SG_ 2147495684 AKit_BrakePedalClearDriverOvrd "Keep the clear driver override flag, though DBW will ignore it if driver is still pressing the brakes";
CM_ SG_ 2147495685 AKit_PrndClearDriverOvrd "What exactly is the function of this?";
CM_ SG_ 2147495685 AKit_PrndCmdWatchdogCntr "Watchdog alive rolling counter";
CM_ BO_ 2147491599 "need to add park assist and blindspot signals here";
CM_ SG_ 2147491599 DBW_OccupAnyAirbagDeployed "true if there has been a crash";
CM_ SG_ 2147491599 DBW_OccupAnySeatbeltUnbuckled "indicates seatbelt warning lamp is on";
CM_ SG_ 2147491599 DBW_DrvInptCruiseResumeBtn "0 = not pressed, 1 = pressed. Cruise buttons are used to enable autonomous driving if pressed in a special combination";
CM_ SG_ 2147491599 DBW_DrvInptCruiseCancelBtn "0 = not pressed, 1 = pressed. Cruise buttons are used to enable autonomous driving if pressed in a special combination";
CM_ SG_ 2147491599 DBW_DrvInptCruiseAccelBtn "0 = not pressed, 1 = pressed. Cruise buttons are used to enable autonomous driving if pressed in a special combination";
CM_ SG_ 2147491599 DBW_DrvInptCruiseDecelBtn "0 = not pressed, 1 = pressed. Cruise buttons are used to enable autonomous driving if pressed in a special combination";
CM_ SG_ 2147491599 DBW_DrvInptCruiseOnOffBtn "0 = not pressed, 1 = pressed. Cruise buttons are used to enable autonomous driving if pressed in a special combination";
CM_ SG_ 2147491599 DBW_DrvInptAccOnOffBtn "0 = not pressed, 1 = pressed. ACC = adaptive cruise";
CM_ SG_ 2147491599 DBW_DrvInptAccIncDistBtn "0 = not pressed, 1 = pressed. ACC = adaptive cruise";
CM_ SG_ 2147491599 DBW_DrvInptAccDecDistBtn "0 = not pressed, 1 = pressed. ACC = adaptive cruise";
CM_ SG_ 2147491591 DBW_TirePressRR "pacifica TPM_A2 scaling goes from 0 to 126, 1 psi per bit. convert to kpa for standard units here.";
CM_ SG_ 2147491591 DBW_TirePressRL "pacifica TPM_A2 scaling goes from 0 to 126, 1 psi per bit. convert to kpa for standard units here.";
CM_ SG_ 2147491591 DBW_TirePressFR "pacifica TPM_A2 scaling goes from 0 to 126, 1 psi per bit. convert to kpa for standard units here.";
CM_ SG_ 2147491591 DBW_TirePressFL "pacifica TPM_A2 scaling goes from 0 to 126, 1 psi per bit. convert to kpa for standard units here.";
CM_ SG_ 2147491592 DBW_VinMultiplexor "message multiplexor";
CM_ BO_ 2147491593 "I think the GPS is on body CAN. do we need to tap into bodyCAN as well...?";
CM_ SG_ 2147491593 DBW_GpsLong "need to determing what \"mas\" scaling is. negative means west.";
CM_ SG_ 2147491593 DBW_GpsLat "need to determing what \"mas\" scaling is. negative means south.";
CM_ BO_ 2147491594 "IMU = Intertial Measurement Unit";
CM_ SG_ 2147491594 DBW_ImuYawRate_Raw "postive = left. scaling matches Pacifica CAN message exactly";
CM_ SG_ 2147491594 DBW_ImuYawRate_Offset "positive = left. not sure what the offset is. Just forwarding right from Pacifica CAN bus";
CM_ SG_ 2147491594 DBW_ImuAccelX_Offset "positive = forward. not sure what the offset is. Just forwarding right from Pacifica CAN bus";
CM_ SG_ 2147491594 DBW_ImuAccelX "postive = forward.";
CM_ SG_ 2147491594 DBW_ImuAccelY "positive = left.";
CM_ SG_ 2147491594 DBW_ImuAccelY_Offset "positive = left.";
CM_ BO_ 2147491595 "we can also get the wheel pulse counters over CAN. would that be more helpful?";
CM_ SG_ 2147491595 DBW_WhlSpd_RR "positive is forward";
CM_ SG_ 2147491595 DBW_WhlSpd_RL "positive is forward";
CM_ SG_ 2147491595 DBW_WhlSpd_FR "positive is forward";
CM_ SG_ 2147491595 DBW_WhlSpd_FL "positive is forward";
CM_ SG_ 2147495686 AKit_MdpmCmdWatchdogCntr "Watchdog alive rolling counter";
CM_ BO_ 992 "This is for reading from the Pacifica bus directly. the FCA DBC doesn't show multiplexing correctly.";
CM_ SG_ 2147491600 DBW_RadarFrontObjDistVld "indicates if the value of front object distance is valid. This will be false when the Radar module is disabled or faulted.";
CM_ SG_ 2147491600 DBW_SonarVld "indicates if the values from the ultrasonic parking sensors are valid. This will be false when the Park Assist module is disabled or faulted.";
CM_ SG_ 2147491600 DBW_SonarRearDist "distance to nearest rear obstacle";
CM_ BO_ 1807 "ASCII names of faults present in the DBW system";
CM_ SG_ 1807 FltTxt_PageNum "Multiplexor";
CM_ SG_ 1807 FltTxt_FaultId "Index of the fault in Raptor. This number is the output of the Raptor Fault Iterator block. this array can also be accessed by the raptor_get_faults() command in MATLAB.";
CM_ SG_ 1807 FltTxt_NumPages "number of pages in the packet for this one fault, varies depending on how many characters in the fault name";
CM_ SG_ 1807 FltTxt_FaultStatus "status of the fault referenced in the current packet";
CM_ SG_ 1807 FltTxt_FaultSetRuntime "timestamp (during current key cycle) when the fault set";
CM_ SG_ 1807 FltTxt_CRC "custom checksum of the fault packet";
CM_ SG_ 1807 FltTxt_CurrentRuntime "current run time (in the current key cycle)";
VAL_ 2147491585 DBW_MiscByWireEnbl 0 "ManualMode" 1 "DriveByWireMode" ;
VAL_ 2147491586 DBW_AccelPdlWatchdogStatus 0 "NONE" 1 "OTHER_BRAKE" 2 "OTHER_ACCEL_PDL" 3 "OTHER_STEERING" 4 "BRAKE_COUNTER" 5 "BRAKE_DISABLED" 6 "BRAKE_COMMAND" 7 "BRAKE_REPORT" 8 "ACCEL_PDL_COUNTER" 9 "ACCEL_PDL_DISABLED" 10 "ACCEL_PDL_COMMAND" 11 "ACCEL_PDL_REPORT" 12 "STEERING_COUNTER" 13 "STEERING_DISABLED" 14 "STEERING_COMMAND" 15 "STEERING_REPORT" ;
VAL_ 2147491587 DBW_SteeringWatchdogStatus 0 "NONE" 1 "OTHER_BRAKE" 2 "OTHER_ACCEL_PDL" 3 "OTHER_STEERING" 4 "BRAKE_COUNTER" 5 "BRAKE_DISABLED" 6 "BRAKE_COMMAND" 7 "BRAKE_REPORT" 8 "ACCEL_PDL_COUNTER" 9 "ACCEL_PDL_DISABLED" 10 "ACCEL_PDL_COMMAND" 11 "ACCEL_PDL_REPORT" 12 "STEERING_COUNTER" 13 "STEERING_DISABLED" 14 "STEERING_COMMAND" 15 "STEERING_REPORT" ;
VAL_ 2147491588 DBW_BrakeWatchdogStatus 0 "NONE" 1 "OTHER_BRAKE" 2 "OTHER_ACCEL_PDL" 3 "OTHER_STEERING" 4 "BRAKE_COUNTER" 5 "BRAKE_DISABLED" 6 "BRAKE_COMMAND" 7 "BRAKE_REPORT" 8 "ACCEL_PDL_COUNTER" 9 "ACCEL_PDL_DISABLED" 10 "ACCEL_PDL_COMMAND" 11 "ACCEL_PDL_REPORT" 12 "STEERING_COUNTER" 13 "STEERING_DISABLED" 14 "STEERING_COMMAND" 15 "STEERING_REPORT" ;
VAL_ 2147491588 DBW_BrakeParkingBrkStatus 0 "Off" 1 "Transitioning" 2 "On" 3 "Fault" ;
VAL_ 2147491589 DBW_PrndStateActual 1 "Park" 2 "Reverse" 3 "Neutral" 4 "Drive" 5 "Low" ;
VAL_ 2147495682 AKit_AccelPdlCtrlMode 0 "Joystick Control" 1 "Full Autonomous Control" ;
VAL_ 2147495681 AKit_TurnSignalCmd 0 "Off" 1 "Left" 2 "Right" 3 "Both_Hazards" ;
VAL_ 2147495681 AKit_DoorToggleReq 0 "NoRequest" 1 "LiftgateToggle" 2 "LeftRearDoorToggle" 3 "RightRearDoorToggle" ;
VAL_ 2147495683 AKit_SteeringWhlCtrlMode 0 "Joystick Control" 1 "Full Autonomous Control" ;
VAL_ 2147495683 AKit_SteeringWhlCmdType 0 "Angle" 1 "Torque" ;
VAL_ 2147495684 AKit_BrakePedalCtrlMode 0 "Joystick Control" 1 "Full Autonomous Control" ;
VAL_ 2147495685 AKit_PrndStateCmd 1 "Park" 2 "Reverse" 3 "Neutral" 4 "Drive" 5 "Low" 0 "No Request" ;
VAL_ 2147491599 DBW_DrvInptHiBeam 0 "Off" 1 "On" 2 "Flash" ;
VAL_ 2147491599 DBW_DrvInptTurnSignal 0 "Off" 1 "Left" 2 "Right" ;
VAL_ 2147491599 DBW_DrvInptWiper 0 "Off" 1 "Interval1" 2 "Interval2" 3 "Interval3" 4 "Interval4" 5 "Interval5" 6 "Interval6" 13 "Constant_Low" 14 "Constant_High" ;
VAL_ 2147491597 DBW_Mdpm1Fuse01 0 "No Fault" 1 "Blown" 2 "Not Powered" 3 "Not Used" ;
VAL_ 2147491597 DBW_Mdpm1Relay01 0 "OK" 1 "Coil Open" 2 "Coil Shorted" 3 "Normally Open contact is open but it should be connected to the Common Terminal" 4 "Normally Closed contact is open but it should be connected to the Common Terminal" 5 "Coil Not Receiving Power" 6 "Normally Open contact is shorted when it should not be connected to the Common Terminal" 7 "Normally Closed contact is shorted when it should not be connected to the Common Terminal" 8 "Reserved" 9 "Reserved" 10 "Reserved" 11 "High-side driver is reporting a fault condition" 12 "High-side driver has an open-load" 13 "High-side driver is over-voltage" 14 "Reserved" 15 "Relay location not used" ;
VAL_ 2147491598 DBW_Mdpm2Fuse01 0 "No Fault" 1 "Blown" 2 "Not Powered" 3 "Not Used" ;
VAL_ 2147491598 DBW_Mdpm2Relay01 0 "OK" 1 "Coil Open" 2 "Coil Shorted" 3 "Normally Open contact is open but it should be connected to the Common Terminal" 4 "Normally Closed contact is open but it should be connected to the Common Terminal" 5 "Coil Not Receiving Power" 6 "Normally Open contact is shorted when it should not be connected to the Common Terminal" 7 "Normally Closed contact is shorted when it should not be connected to the Common Terminal" 8 "Reserved" 9 "Reserved" 10 "Reserved" 11 "High-side driver is reporting a fault condition" 12 "High-side driver has an open-load" 13 "High-side driver is over-voltage" 14 "Reserved" 15 "Relay location not used" ;
VAL_ 2147495686 AKit_Mdpm1Relay01Cmd 0 "Turn relay off" 1 "Turn relay on" 2 "Do not change relay state" 3 "Do not change relay state" ;
VAL_ 2147495686 AKit_Mdpm1Relay02Cmd 0 "Turn relay off" 1 "Turn relay on" 2 "Do not change relay state" 3 "Do not change relay state" ;
VAL_ 2147495686 AKit_Mdpm1Relay03Cmd 0 "Turn relay off" 1 "Turn relay on" 2 "Do not change relay state" 3 "Do not change relay state" ;
VAL_ 2147495686 AKit_Mdpm1Relay04Cmd 0 "Turn relay off" 1 "Turn relay on" 2 "Do not change relay state" 3 "Do not change relay state" ;
VAL_ 2147495686 AKit_Mdpm1Relay05Cmd 0 "Turn relay off" 1 "Turn relay on" 2 "Do not change relay state" 3 "Do not change relay state" ;
VAL_ 2147495686 AKit_Mdpm1Relay06Cmd 0 "Turn relay off" 1 "Turn relay on" 2 "Do not change relay state" 3 "Do not change relay state" ;
VAL_ 2147495686 AKit_Mdpm1Relay07Cmd 0 "Turn relay off" 1 "Turn relay on" 2 "Do not change relay state" 3 "Do not change relay state" ;
VAL_ 2147495686 AKit_Mdpm1Relay08Cmd 0 "Turn relay off" 1 "Turn relay on" 2 "Do not change relay state" 3 "Do not change relay state" ;
VAL_ 2147495686 AKit_Mdpm2Relay01Cmd 0 "Turn relay off" 1 "Turn relay on" 2 "Do not change relay state" 3 "Do not change relay state" ;
VAL_ 2147495686 AKit_Mdpm2Relay02Cmd 0 "Turn relay off" 1 "Turn relay on" 2 "Do not change relay state" 3 "Do not change relay state" ;
VAL_ 2147495686 AKit_Mdpm2Relay03Cmd 0 "Turn relay off" 1 "Turn relay on" 2 "Do not change relay state" 3 "Do not change relay state" ;
VAL_ 2147495686 AKit_Mdpm2Relay04Cmd 0 "Turn relay off" 1 "Turn relay on" 2 "Do not change relay state" 3 "Do not change relay state" ;
VAL_ 2147495686 AKit_Mdpm2Relay05Cmd 0 "Turn relay off" 1 "Turn relay on" 2 "Do not change relay state" 3 "Do not change relay state" ;
VAL_ 2147495686 AKit_Mdpm2Relay06Cmd 0 "Turn relay off" 1 "Turn relay on" 2 "Do not change relay state" 3 "Do not change relay state" ;
VAL_ 2147495686 AKit_Mdpm2Relay07Cmd 0 "Turn relay off" 1 "Turn relay on" 2 "Do not change relay state" 3 "Do not change relay state" ;
VAL_ 2147495686 AKit_Mdpm2Relay08Cmd 0 "Turn relay off" 1 "Turn relay on" 2 "Do not change relay state" 3 "Do not change relay state" ;
VAL_ 2147491600 DBW_SonarArcNumRR 15 "No ARC" 8 "ARC8" 7 "ARC7" 6 "ARC6" 5 "ARC5" 4 "ARC4" 3 "ARC3" 2 "ARC2" 1 "ARC1" 0 "NODist" ;
VAL_ 2147491600 DBW_SonarArcNumRL 15 "No ARC" 8 "ARC8" 7 "ARC7" 6 "ARC6" 5 "ARC5" 4 "ARC4" 3 "ARC3" 2 "ARC2" 1 "ARC1" 0 "NODist" ;
VAL_ 2147491600 DBW_SonarArcNumRC 15 "No ARC" 8 "ARC8" 7 "ARC7" 6 "ARC6" 5 "ARC5" 4 "ARC4" 3 "ARC3" 2 "ARC2" 1 "ARC1" 0 "NODist" ;
VAL_ 2147491600 DBW_SonarArcNumFR 15 "No ARC" 8 "ARC8" 7 "ARC7" 6 "ARC6" 5 "ARC5" 4 "ARC4" 3 "ARC3" 2 "ARC2" 1 "ARC1" 0 "NODist" ;
VAL_ 2147491600 DBW_SonarArcNumFL 15 "No ARC" 8 "ARC8" 7 "ARC7" 6 "ARC6" 5 "ARC5" 4 "ARC4" 3 "ARC3" 2 "ARC2" 1 "ARC1" 0 "NODist" ;
VAL_ 2147491600 DBW_SonarArcNumFC 15 "No ARC" 8 "ARC8" 7 "ARC7" 6 "ARC6" 5 "ARC5" 4 "ARC4" 3 "ARC3" 2 "ARC2" 1 "ARC1" 0 "NODist" ;
VAL_ 1807 FltTxt_FaultStatus 1 "Occurred" 2 "Active" ;
